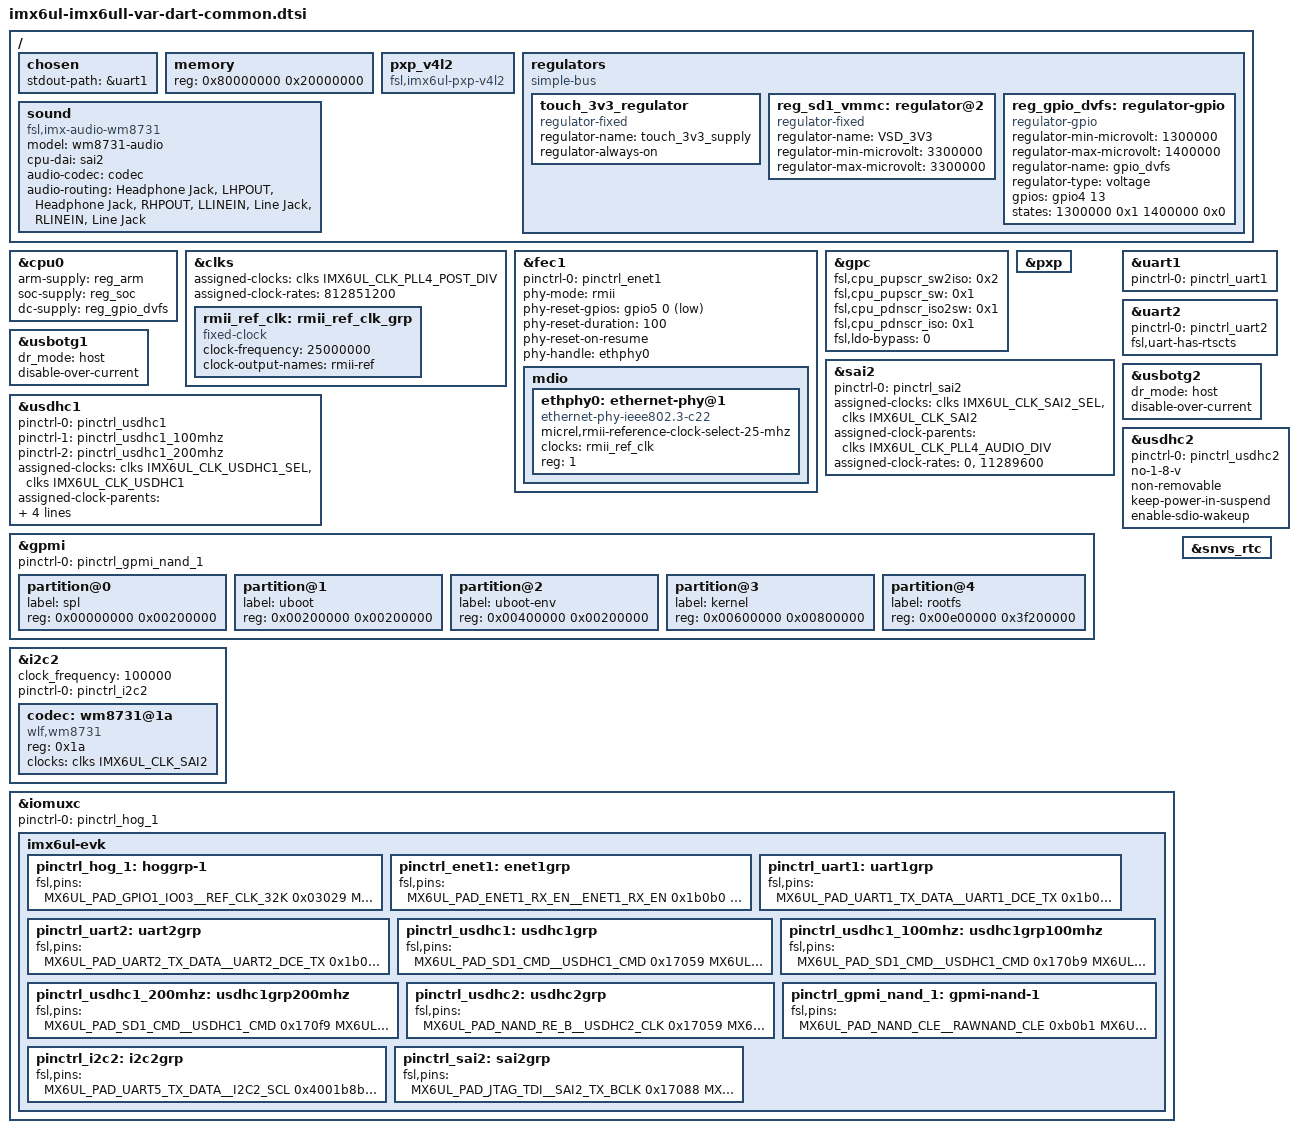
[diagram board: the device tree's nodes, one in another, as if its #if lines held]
/*
 * Copyright (C) 2015 Freescale Semiconductor, Inc.
 *
 * Copyright (C) 2015-2016 Variscite Ltd. - http://www.variscite.com
 *
 * This program is free software; you can redistribute it and/or modify
 * it under the terms of the GNU General Public License version 2 as
 * published by the Free Software Foundation.
 */
/* #define WIFI */
/* #define EMMC */
/* #define  NAND  */

/ {
	chosen {
		stdout-path = &uart1;
	};

	memory {
		reg = <0x80000000 0x20000000>;
	};

	pxp_v4l2 {
		compatible = "fsl,imx6ul-pxp-v4l2", "fsl,imx6sx-pxp-v4l2", "fsl,imx6sl-pxp-v4l2";
		status = "okay";
	};

	regulators {
		compatible = "simple-bus";
		#address-cells = <1>;
		#size-cells = <0>;

		touch_3v3_regulator: touch_3v3_regulator {
			compatible = "regulator-fixed";
			regulator-name = "touch_3v3_supply";
			regulator-always-on;
			status = "okay";
		};

		reg_sd1_vmmc: regulator@2 {
			compatible = "regulator-fixed";
			regulator-name = "VSD_3V3";
			regulator-min-microvolt = <3300000>;
			regulator-max-microvolt = <3300000>;
		};

		reg_gpio_dvfs: regulator-gpio {
			compatible = "regulator-gpio";
			regulator-min-microvolt = <1300000>;
			regulator-max-microvolt = <1400000>;
			regulator-name = "gpio_dvfs";
			regulator-type = "voltage";
			gpios = <&gpio4 13 GPIO_ACTIVE_HIGH>;
			states = <1300000 0x1 1400000 0x0>;
		};
	};

#ifdef AC
	sound {
		compatible = "fsl,imx-audio-wm8731";
		model = "wm8731-audio";
		cpu-dai = <&sai2>;
		audio-codec = <&codec>;
		audio-routing =
			"Headphone Jack",	"LHPOUT",
			"Headphone Jack",	"RHPOUT",
			"LLINEIN",		"Line Jack",
			"RLINEIN",		"Line Jack";
	};
#endif
};

&cpu0 {
	arm-supply = <&reg_arm>;
	soc-supply = <&reg_soc>;
	dc-supply = <&reg_gpio_dvfs>;
};

&clks {
	/* ref_clk for micrel ethernet phy */
	rmii_ref_clk: rmii_ref_clk_grp {
		compatible = "fixed-clock";
		#clock-cells = <0>;
		clock-frequency = <25000000>;
		clock-output-names = "rmii-ref";
	};
};

&clks {
	assigned-clocks = <&clks IMX6UL_CLK_PLL4_POST_DIV>;
	assigned-clock-rates = <812851200>;
};

#ifdef PHY
&fec1 {
	pinctrl-names = "default";
	pinctrl-0 = <&pinctrl_enet1>;
	phy-mode = "rmii";
	phy-reset-gpios=<&gpio5 0 1>;
	phy-reset-duration=<100>;
	phy-reset-on-resume;
	phy-handle = <&ethphy0>;
	status = "okay";
	mdio {
		#address-cells = <1>;
		#size-cells = <0>;

		ethphy0: ethernet-phy@1 {
			compatible = "ethernet-phy-ieee802.3-c22";
			micrel,rmii-reference-clock-select-25-mhz;
			clocks = <&rmii_ref_clk>;
			clock-names = "rmii-ref";
			reg = <1>;
		};
	};
};
#endif

&gpc {
	fsl,cpu_pupscr_sw2iso = <0x2>;
	fsl,cpu_pupscr_sw = <0x1>;
	fsl,cpu_pdnscr_iso2sw = <0x1>;
	fsl,cpu_pdnscr_iso = <0x1>;
	fsl,ldo-bypass = <0>; /* DCDC, ldo-enable */
};

&pxp {
	status = "okay";
};

#ifdef AC
&sai2 {
	pinctrl-names = "default";
	pinctrl-0 = <&pinctrl_sai2>;
	assigned-clocks = <&clks IMX6UL_CLK_SAI2_SEL>,<&clks IMX6UL_CLK_SAI2>;
	assigned-clock-parents = <&clks IMX6UL_CLK_PLL4_AUDIO_DIV>;
	assigned-clock-rates = <0>, <11289600>;
	status = "okay";
};
#endif

/* Console UART */
&uart1 {
	pinctrl-names = "default";
	pinctrl-0 = <&pinctrl_uart1>;
	status = "okay";
};

/* Bluetooth UART */
&uart2 {
	pinctrl-names = "default";
	pinctrl-0 = <&pinctrl_uart2>;
	fsl,uart-has-rtscts;
	status = "okay";
};

&usbotg1 {
	dr_mode = "host";
	disable-over-current;
	status = "okay";
};

&usbotg2 {
	dr_mode = "host";
	disable-over-current;
	status = "okay";
};

#ifdef WIFI_5G
/*  Wi-Fi/BT SD Card Slot Definition */

&usdhc1 {
	pinctrl-names = "default", "state_100mhz", "state_200mhz";
	pinctrl-0 = <&pinctrl_usdhc1>;
	pinctrl-1 = <&pinctrl_usdhc1_100mhz>;
	pinctrl-2 = <&pinctrl_usdhc1_200mhz>;
	assigned-clocks = <&clks IMX6UL_CLK_USDHC1_SEL>, <&clks IMX6UL_CLK_USDHC1>;
	assigned-clock-parents = <&clks IMX6UL_CLK_PLL2_PFD2>;
	assigned-clock-rates = <0>, <132000000>;
	fsl,tuning-step= <2>;
	vmmc-supply = <&reg_sd1_vmmc>;
	status = "okay";
};
#else
&usdhc1 {
	pinctrl-names = "default", "state_100mhz", "state_200mhz";
	pinctrl-0 = <&pinctrl_usdhc1>;
	pinctrl-1 = <&pinctrl_usdhc1_100mhz>;
	pinctrl-2 = <&pinctrl_usdhc1_200mhz>;
	no-1-8-v;
	keep-power-in-suspend;
	vmmc-supply = <&reg_sd1_vmmc>;
	non-removable;
	status = "okay";
};
#endif /* WIFI_5G */

#ifdef NAND
&gpmi {
	pinctrl-names = "default";
	pinctrl-0 = <&pinctrl_gpmi_nand_1>;
	status = "okay";

	partition@0 {
		label = "spl";
		reg = <0x00000000 0x00200000>;
	};

	partition@1 {
		label = "uboot";
		reg = <0x00200000 0x00200000>;
	};

	partition@2 {
		label = "uboot-env";
		reg = <0x00400000 0x00200000>;
	};

	partition@3 {
		label = "kernel";
		reg = <0x00600000 0x00800000>;
	};

	partition@4 {
		label = "rootfs";
		reg = <0x00e00000 0x3f200000>;
	};
};

&usdhc2 {
	status = "disabled";
};
#endif

#ifdef EMMC
&usdhc2 {
	pinctrl-names = "default";
	pinctrl-0 = <&pinctrl_usdhc2>;
	no-1-8-v;
	non-removable;
	keep-power-in-suspend;
	enable-sdio-wakeup;
	status = "okay";
};
#endif

&i2c2 {
	clock_frequency = <100000>;
	pinctrl-names = "default";
	pinctrl-0 = <&pinctrl_i2c2>;
	status = "okay";
	
#ifdef AC
	codec: wm8731@1a {
		compatible = "wlf,wm8731";
		reg = <0x1a>;
		clocks = <&clks IMX6UL_CLK_SAI2>;
		clock-names = "mclk";
	};
#endif

};

&iomuxc {
	pinctrl-names = "default";
	pinctrl-0 = <&pinctrl_hog_1>;
	imx6ul-evk {
		pinctrl_hog_1: hoggrp-1 {
			fsl,pins = <
				MX6UL_PAD_GPIO1_IO03__REF_CLK_32K	0x03029	/* WLAN Slow Clock */
#ifdef PHY
				MX6UL_PAD_GPIO1_IO07__ENET1_MDC		0x1b0b0
				MX6UL_PAD_GPIO1_IO06__ENET1_MDIO	0x1b0b0
#else
				MX6UL_PAD_GPIO1_IO07__GPIO1_IO07	0x1b0b0
				MX6UL_PAD_GPIO1_IO06__GPIO1_IO06	0x1b0b0
				MX6UL_PAD_ENET1_RX_EN__GPIO2_IO02	0x1b0b0
				MX6UL_PAD_ENET1_RX_ER__GPIO2_IO07	0x1b0b0
				MX6UL_PAD_ENET1_RX_DATA0__GPIO2_IO00	0x1b0b0
				MX6UL_PAD_ENET1_RX_DATA1__GPIO2_IO01	0x1b0b0
				MX6UL_PAD_ENET1_TX_EN__GPIO2_IO05	0x1b0b0
				MX6UL_PAD_ENET1_TX_DATA0__GPIO2_IO03	0x1b0b0
				MX6UL_PAD_ENET1_TX_DATA1__GPIO2_IO04	0x1b0b0
				MX6UL_PAD_ENET1_TX_CLK__GPIO2_IO06	0x1b0b0
#endif
				MX6UL_PAD_JTAG_MOD__GPIO1_IO10		0x1b0b0
				MX6UL_PAD_CSI_DATA03__GPIO4_IO24	0x1b0b0
				MX6UL_PAD_GPIO1_IO00__GPIO1_IO00	0x1b0b0
				MX6UL_PAD_UART4_TX_DATA__GPIO1_IO28	0x1b0b0
				MX6UL_PAD_UART4_RX_DATA__GPIO1_IO29	0x1b0b0
				MX6UL_PAD_GPIO1_IO05__GPIO1_IO05	0x1b0b0
				MX6UL_PAD_UART1_CTS_B__GPIO1_IO18	0x1b0b0
				MX6UL_PAD_UART1_RTS_B__GPIO1_IO19	0x1b0b0
/*				
#ifndef AC
				MX6UL_PAD_JTAG_TDI__GPIO1_IO13		0x1b0b0
				MX6UL_PAD_JTAG_TDO__GPIO1_IO12		0x1b0b0
				MX6UL_PAD_JTAG_TRST_B__GPIO1_IO15	0x1b0b0
				MX6UL_PAD_JTAG_TCK__GPIO1_IO14		0x1b0b0
				MX6UL_PAD_JTAG_TMS__GPIO1_IO11		0x1b0b0
#endif
*/				>;
		};
		
#ifdef PHY
		pinctrl_enet1: enet1grp {
			fsl,pins = <
				MX6UL_PAD_ENET1_RX_EN__ENET1_RX_EN	0x1b0b0
				MX6UL_PAD_ENET1_RX_ER__ENET1_RX_ER	0x1b0b0
				MX6UL_PAD_ENET1_RX_DATA0__ENET1_RDATA00	0x1b0b0
				MX6UL_PAD_ENET1_RX_DATA1__ENET1_RDATA01	0x1b0b0
				MX6UL_PAD_ENET1_TX_EN__ENET1_TX_EN	0x1b0b0
				MX6UL_PAD_ENET1_TX_DATA0__ENET1_TDATA00	0x1b0b0
				MX6UL_PAD_ENET1_TX_DATA1__ENET1_TDATA01	0x1b0b0
				MX6UL_PAD_ENET1_TX_CLK__ENET1_REF_CLK1	0x4001b031
			>;
		};
#endif

		pinctrl_uart1: uart1grp {
			fsl,pins = <
				MX6UL_PAD_UART1_TX_DATA__UART1_DCE_TX	0x1b0b1
				MX6UL_PAD_UART1_RX_DATA__UART1_DCE_RX	0x1b0b1
			>;
		};

		pinctrl_uart2: uart2grp {
			fsl,pins = <
				MX6UL_PAD_UART2_TX_DATA__UART2_DCE_TX	0x1b0b1
				MX6UL_PAD_UART2_RX_DATA__UART2_DCE_RX	0x1b0b1
				MX6UL_PAD_UART2_CTS_B__UART2_DCE_CTS	0x1b0b1
				MX6UL_PAD_UART2_RTS_B__UART2_DCE_RTS	0x1b0b1
			>;
		};

		pinctrl_usdhc1: usdhc1grp {
			fsl,pins = <
				MX6UL_PAD_SD1_CMD__USDHC1_CMD		0x17059
				MX6UL_PAD_SD1_CLK__USDHC1_CLK		0x17059
				MX6UL_PAD_SD1_DATA0__USDHC1_DATA0	0x17059
				MX6UL_PAD_SD1_DATA1__USDHC1_DATA1	0x17059
				MX6UL_PAD_SD1_DATA2__USDHC1_DATA2	0x17059
				MX6UL_PAD_SD1_DATA3__USDHC1_DATA3	0x17059
				MX6UL_PAD_CSI_VSYNC__GPIO4_IO19		0x1b0b1	/* SD card detect */
			>;
		};

		pinctrl_usdhc1_100mhz: usdhc1grp100mhz {
			fsl,pins = <
				MX6UL_PAD_SD1_CMD__USDHC1_CMD		0x170b9
				MX6UL_PAD_SD1_CLK__USDHC1_CLK		0x100b9
				MX6UL_PAD_SD1_DATA0__USDHC1_DATA0	0x170b9
				MX6UL_PAD_SD1_DATA1__USDHC1_DATA1	0x170b9
				MX6UL_PAD_SD1_DATA2__USDHC1_DATA2	0x170b9
				MX6UL_PAD_SD1_DATA3__USDHC1_DATA3	0x170b9
				MX6UL_PAD_CSI_VSYNC__GPIO4_IO19		0x1b0b1	/* SD card detect */
			>;
		};

		pinctrl_usdhc1_200mhz: usdhc1grp200mhz {
			fsl,pins = <
				MX6UL_PAD_SD1_CMD__USDHC1_CMD		0x170f9
				MX6UL_PAD_SD1_CLK__USDHC1_CLK		0x100f9
				MX6UL_PAD_SD1_DATA0__USDHC1_DATA0	0x170f9
				MX6UL_PAD_SD1_DATA1__USDHC1_DATA1	0x170f9
				MX6UL_PAD_SD1_DATA2__USDHC1_DATA2	0x170f9
				MX6UL_PAD_SD1_DATA3__USDHC1_DATA3	0x170f9
				MX6UL_PAD_CSI_VSYNC__GPIO4_IO19		0x1b0b1	/* SD card detect */
			>;
		};
#ifdef EMMC
		pinctrl_usdhc2: usdhc2grp {
			fsl,pins = <
				MX6UL_PAD_NAND_RE_B__USDHC2_CLK		0x17059
				MX6UL_PAD_NAND_WE_B__USDHC2_CMD		0x17059
				MX6UL_PAD_NAND_DATA00__USDHC2_DATA0	0x17059
				MX6UL_PAD_NAND_DATA01__USDHC2_DATA1	0x17059
				MX6UL_PAD_NAND_DATA02__USDHC2_DATA2	0x17059
				MX6UL_PAD_NAND_DATA03__USDHC2_DATA3	0x17059
			>;
		};
#endif
#ifdef NAND
		pinctrl_gpmi_nand_1: gpmi-nand-1 {
			fsl,pins = <
				MX6UL_PAD_NAND_CLE__RAWNAND_CLE		0xb0b1
				MX6UL_PAD_NAND_ALE__RAWNAND_ALE		0xb0b1
				MX6UL_PAD_NAND_WP_B__RAWNAND_WP_B	0xb0b1
				MX6UL_PAD_NAND_READY_B__RAWNAND_READY_B	0xb000
				MX6UL_PAD_NAND_CE0_B__RAWNAND_CE0_B	0xb0b1
				MX6UL_PAD_NAND_RE_B__RAWNAND_RE_B	0xb0b1
				MX6UL_PAD_NAND_WE_B__RAWNAND_WE_B	0xb0b1
				MX6UL_PAD_NAND_DATA00__RAWNAND_DATA00	0xb0b1
				MX6UL_PAD_NAND_DATA01__RAWNAND_DATA01	0xb0b1
				MX6UL_PAD_NAND_DATA02__RAWNAND_DATA02	0xb0b1
				MX6UL_PAD_NAND_DATA03__RAWNAND_DATA03	0xb0b1
				MX6UL_PAD_NAND_DATA04__RAWNAND_DATA04	0xb0b1
				MX6UL_PAD_NAND_DATA05__RAWNAND_DATA05	0xb0b1
				MX6UL_PAD_NAND_DATA06__RAWNAND_DATA06	0xb0b1
				MX6UL_PAD_NAND_DATA07__RAWNAND_DATA07	0xb0b1
			>;
		};
#endif

		pinctrl_i2c2: i2c2grp {
			fsl,pins = <
				MX6UL_PAD_UART5_TX_DATA__I2C2_SCL	0x4001b8b0
				MX6UL_PAD_UART5_RX_DATA__I2C2_SDA	0x4001b8b0
			>;
		};
		
#ifdef AC
		pinctrl_sai2: sai2grp {
			fsl,pins = <
				MX6UL_PAD_JTAG_TDI__SAI2_TX_BCLK	0x17088
				MX6UL_PAD_JTAG_TDO__SAI2_TX_SYNC	0x17088
				MX6UL_PAD_JTAG_TRST_B__SAI2_TX_DATA	0x11088
				MX6UL_PAD_JTAG_TCK__SAI2_RX_DATA	0x11088
				MX6UL_PAD_JTAG_TMS__CCM_CLKO1		0x17088
			>;
		};
#endif
	};
};

&snvs_rtc {
       status = "okay";
};

